# regs-internal register map
Registers are 32-bit, access not given, no defined reset value unless marked. A register's access mark holds for its fields unless they carry their own. Addresses are absolute; registers are grouped by the start of their names; [hi:lo] are bit positions.

## WAKE
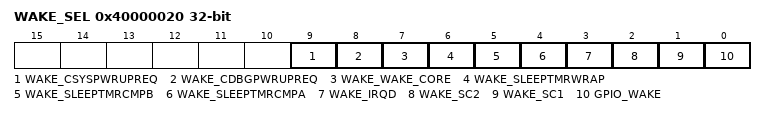
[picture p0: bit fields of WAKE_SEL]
0x40000020 WAKE_SEL
  [9] WAKE_CSYSPWRUPREQ, [8] WAKE_CDBGPWRUPREQ, [7] WAKE_WAKE_CORE, [6] WAKE_SLEEPTMRWRAP, [5] WAKE_SLEEPTMRCMPB, [4] WAKE_SLEEPTMRCMPA, [3] WAKE_IRQD, [2] WAKE_SC2, [1] WAKE_SC1, [0] GPIO_WAKE
0x40000024 WAKE_CORE
  [5] WAKE_CORE_FIELD

## CSYSPWRUPACK
0x4000003C CSYSPWRUPACK_STATUS
  [0] CSYSPWRUPACK
0x40000040 CSYSPWRUPACK_INHIBIT
  [0] CSYSPWRUPACK_INHIBIT

## OPT
0x40000044 OPT_ERR_MAINTAIN_WAKE
  [0] OPT_ERR_MAINTAIN_WAKE
0x40008008 OPT_KEY
  [31:0] OPTKEYR
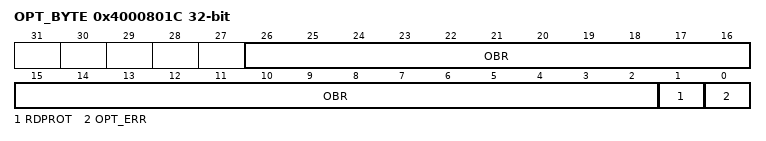
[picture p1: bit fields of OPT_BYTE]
0x4000801C OPT_BYTE
  [26:2] OBR, [1] RDPROT, [0] OPT_ERR

## MOD
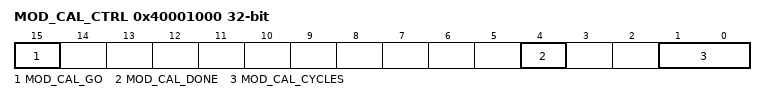
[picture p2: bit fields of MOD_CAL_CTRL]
0x40001000 MOD_CAL_CTRL
  [15] MOD_CAL_GO, [4] MOD_CAL_DONE, [1:0] MOD_CAL_CYCLES
0x40001004 MOD_CAL_COUNT_H
  [7:0] MOD_CAL_COUNT_H
0x40001008 MOD_CAL_COUNT_L
  [15:0] MOD_CAL_COUNT_L
0x40001028 MOD_EN
  [0] MOD_EN

## RSSI
0x4000100C RSSI_ROLLING
  [13:0] RSSI_ROLLING
0x40001010 RSSI_PKT
  [7:0] RSSI_PKT
0x40001054 RSSI_THRESH
  [15:0] RSSI_THRESH
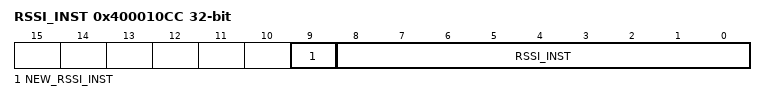
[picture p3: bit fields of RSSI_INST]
0x400010CC RSSI_INST
  [9] NEW_RSSI_INST, [8:0] RSSI_INST

## RX
0x40001014 RX_ADC
  [6:0] RX_ADC
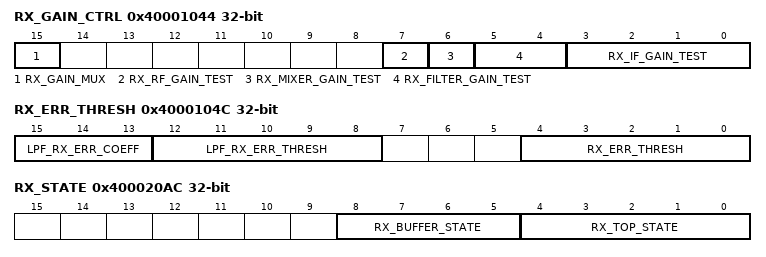
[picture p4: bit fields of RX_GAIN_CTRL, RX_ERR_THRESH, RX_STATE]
0x40001044 RX_GAIN_CTRL
  [15] RX_GAIN_MUX, [7] RX_RF_GAIN_TEST, [6] RX_MIXER_GAIN_TEST, [5:4] RX_FILTER_GAIN_TEST, [3:0] RX_IF_GAIN_TEST
0x4000104C RX_ERR_THRESH
  [15:13] LPF_RX_ERR_COEFF, [12:8] LPF_RX_ERR_THRESH, [4:0] RX_ERR_THRESH
0x40002020 RX_A_COUNT
  [10:0] RX_A_COUNT
0x40002024 RX_B_COUNT
  [10:0] RX_B_COUNT
0x40002070 RX_CRC
  [15:0] RX_CRC
0x400020AC RX_STATE
  [8:5] RX_BUFFER_STATE, [4:0] RX_TOP_STATE
0x40009024 RX_ADC_MUX
  [1:0] RX_ADC_MUX

## DEBUG
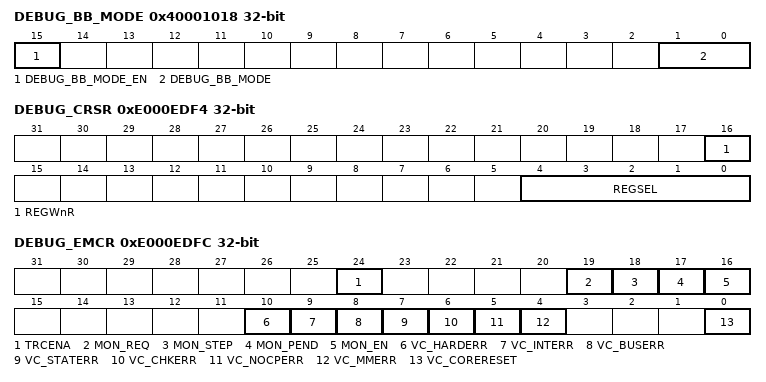
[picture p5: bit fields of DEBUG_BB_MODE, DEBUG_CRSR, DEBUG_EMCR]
0x40001018 DEBUG_BB_MODE
  [15] DEBUG_BB_MODE_EN, [1:0] DEBUG_BB_MODE
0xE000EDF0 DEBUG_HCSR
  [25] S_RESET_ST, [24] S_RETIRE_ST, [19] S_LOCKUP, [18] S_SLEEP, [17] S_HALT, [16] S_REGRDY, [31:16] DBGKEY, [5] C_SNAPSTALL, [3] C_MASKINTS, [2] C_STEP, [1] C_HALT, [0] C_DEBUGEN
0xE000EDF4 DEBUG_CRSR
  [16] REGWnR, [4:0] REGSEL
0xE000EDF8 DEBUG_CRDR
  [31:0] DBGTMP
0xE000EDFC DEBUG_EMCR
  [24] TRCENA, [19] MON_REQ, [18] MON_STEP, [17] MON_PEND, [16] MON_EN, [10] VC_HARDERR, [9] VC_INTERR, [8] VC_BUSERR, [7] VC_STATERR, [6] VC_CHKERR, [5] VC_NOCPERR, [4] VC_MMERR, [0] VC_CORERESET

## BB
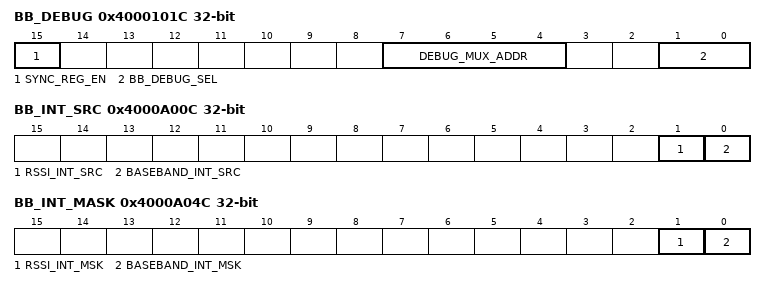
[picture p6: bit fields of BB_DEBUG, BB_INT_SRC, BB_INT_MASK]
0x4000101C BB_DEBUG
  [15] SYNC_REG_EN, [7:4] DEBUG_MUX_ADDR, [1:0] BB_DEBUG_SEL
0x40001020 BB_DEBUG_VIEW
  [15:0] BB_DEBUG_VIEW
0x4000A00C BB_INT_SRC
  [1] RSSI_INT_SRC, [0] BASEBAND_INT_SRC
0x4000A04C BB_INT_MASK
  [1] RSSI_INT_MSK, [0] BASEBAND_INT_MSK

## ADC
0x40001030 ADC_BYPASS_EN
  [0] ADC_BYPASS_EN
0x4000D000 ADC_DATA
  [15:0] ADC_DATA_FIELD
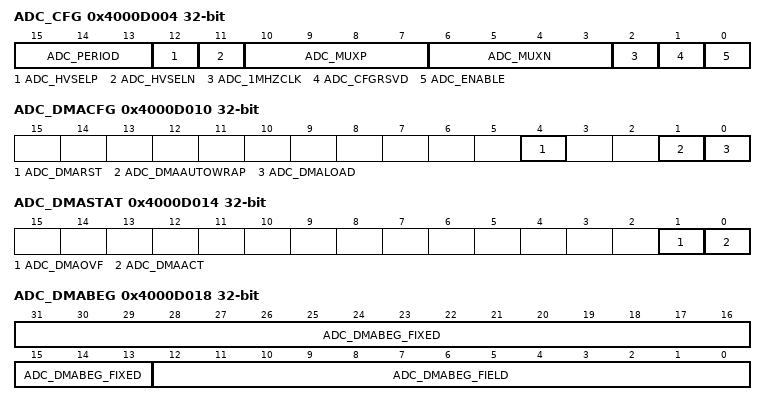
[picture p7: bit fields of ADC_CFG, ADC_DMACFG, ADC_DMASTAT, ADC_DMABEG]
0x4000D004 ADC_CFG
  [15:13] ADC_PERIOD, [12] ADC_HVSELP, [11] ADC_HVSELN, [10:7] ADC_MUXP, [6:3] ADC_MUXN, [2] ADC_1MHZCLK, [1] ADC_CFGRSVD, [0] ADC_ENABLE
0x4000D008 ADC_OFFSET
  [15:0] ADC_OFFSET_FIELD
0x4000D00C ADC_GAIN
  [15:0] ADC_GAIN_FIELD
0x4000D010 ADC_DMACFG
  [4] ADC_DMARST, [1] ADC_DMAAUTOWRAP, [0] ADC_DMALOAD
0x4000D014 ADC_DMASTAT
  [1] ADC_DMAOVF, [0] ADC_DMAACT
0x4000D018 ADC_DMABEG
  [31:13] ADC_DMABEG_FIXED, [12:0] ADC_DMABEG_FIELD
0x4000D01C ADC_DMASIZE
  [11:0] ADC_DMASIZE_FIELD
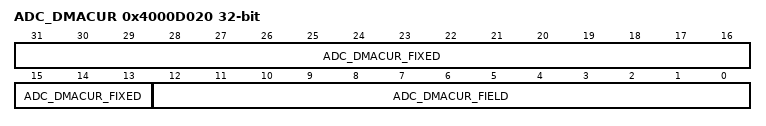
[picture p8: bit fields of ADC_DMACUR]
0x4000D020 ADC_DMACUR
  [31:13] ADC_DMACUR_FIXED, [12:0] ADC_DMACUR_FIELD
0x4000D024 ADC_DMACNT
  [11:0] ADC_DMACNT_FIELD

## FIXED
0x40001034 FIXED_CODE_EN
  [0] FIXED_CODE_EN
0x40001038 FIXED_CODE_H
  [15:0] FIXED_CODE_H
0x4000103C FIXED_CODE_L
  [15:0] FIXED_CODE_L
0x40001040 FIXED_CODE_L_SHADOW
  [15:0] FIXED_CODE_L_SHADOW

## SYNTH
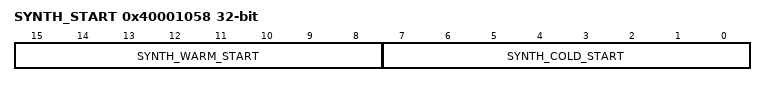
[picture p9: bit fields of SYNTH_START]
0x40001058 SYNTH_START
  [15:8] SYNTH_WARM_START, [7:0] SYNTH_COLD_START
0x400010C4 SYNTH_FREQ_H
  [1:0] SYNTH_FREQ_H
0x400010C8 SYNTH_FREQ_L
  [15:0] SYNTH_FREQ_L
0x400010FC SYNTH_LOCK
  [0] IN_LOCK
